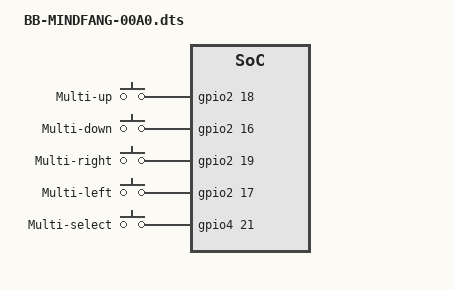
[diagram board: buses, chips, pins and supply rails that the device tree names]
/dts-v1/;
/plugin/;

/ {
    compatible = "ti,beaglebone", "ti,beaglebone-black";

    /* identification */
    part-number = "BB-MINDFANG";
    version = "00A0";

    fragment@0 {
        target = <&am33xx_pinmux>;
        __overlay__ {
            multi_pins: pinmux_multi_pins{
                pinctrl-single,pins = <
                    0x048 0x27 // P9_14 = Multi up     = GPIO1_18 EHRPWM1A
                    0x040 0x27 // P9_15 = Multi down   = GPIO1_16
                    0x04C 0x27 // P9_16 = Multi right  = GPIO1_19 EHRPWM1B
                    0x044 0x27 // P9_23 = Multi left   = GPIO1_17
                    0x1AC 0x27 // P9_25 = Multi select = GPIO3_21
                >;
            };
        };
    };

    fragment@1 {
        target = <&ocp>;
        __overlay__ {
            #address-cells = <1>;
            #size-cells = <1>;

            gpio_keys {
                compatible = "gpio-keys";
                autorepeat;
                pinctrl-names = "default";
                pinctrl-0 = <&multi_pins>;
                #address-cells = <1>;
                #size-cells = <0>;

                switch_multi_up {
                    label = "Multi-up";
                    debounce_interval = <50>;
                    linux,code = <1>;
                    gpios = <&gpio2 18 0x4>;
                    gpio-key,wakeup;
                };
                switch_multi_down {
                    label = "Multi-down";
                    debounce_interval = <50>;
                    linux,code = <2>;
                    gpios = <&gpio2 16 0x4>;
                    gpio-key,wakeup;
                };
                switch_multi_right {
                    label = "Multi-right";
                    debounce_interval = <50>;
                    linux,code = <3>;
                    gpios = <&gpio2 19 0x4>;
                    gpio-key,wakeup;
                };
                switch_multi_left {
                    label = "Multi-left";
                    debounce_interval = <50>;
                    linux,code = <4>;
                    gpios = <&gpio2 17 0x4>;
                    gpio-key,wakeup;
                };
                switch_multi_select {
                    label = "Multi-select";
                    debounce_interval = <50>;
                    linux,code = <5>;
                    gpios = <&gpio4 21 0x4>;
                    gpio-key,wakeup;
                };
            };
        };
    };
};
